# CY8C5888LTI_LP097 register map
File version: 0.1
CY8C58LP
Registers are 8-bit, read-write, no defined reset value unless marked. A register's access mark holds for its fields unless they carry their own. Offsets are from the block's base; lines under a group give offsets from that group; [hi:lo] are bit positions; {n}, {i} and the like mark numbered series; 'fields as' and 'values as' point back to an identical list; <NAME> marks a mode.

## Memory map
0x00000000 ADC_STATUS
0x00000000 BLINK_25HZ
0x00000000 ADC_SOC
0x00000000 ADC
0x00000000 BLINK_05HZ
0x00000000 LED_CTRL
0x00000000 BLINK_CTRL_EN
0x00000000 MOTOR_ON_OFF_1
0x00000000 VT1_DIR
0x00000000 VT2_DIR
0x00000000 MOTOR_DIR_1
0x00000000 PWM_MOTORS
0x00000000 PWM_VT
0x00000000 ADC_N_CHANNELS_USED
0x00000000 MY_TIMER_REG
0x00000000 MOTOR_ON_OFF_2
0x00000000 MOTOR_DRIVER_TYPE
0x00000000 CYCLES_TIMER
0x00000000 MOTOR_DIR_2
0x00000000 PACER_TIMER
0x00000000 RESET_FF
0x00000000 UART_RS485 — UART
0x00000000 FF_STATUS
0x00000000 MY_TIMER

## ADC_STATUS
Base 0x00000000
0x40006462 ADC_STATUS_STATUS_REG
0x40006482 ADC_STATUS_MASK_REG
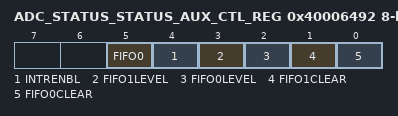
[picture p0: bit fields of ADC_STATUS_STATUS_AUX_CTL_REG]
0x40006492 ADC_STATUS_STATUS_AUX_CTL_REG
  [5] FIFO0 — FIFO0 clear
    1=ENABLED (Enable counter); 0=DISABLED (Disable counter)
  [4] INTRENBL — Enables or disables the Interrupt
    1=ENABLED (Interrupt enabled); 0=DISABLED (Interrupt disabled)
  [3] FIFO1LEVEL — FIFO level
    1=ENABLED (FIFO LVL: input mode: FIFO at least 1/2 empty; output mode: FIFO at least 1/2 full); 0=DISABLED (FIFO LVL: input mode: FIFO not full; output mode: FIFO not empty)
  [2] FIFO0LEVEL — FIFO level
    values as FIFO1LEVEL
  [1] FIFO1CLEAR — FIFO clear
    1=ENABLED (Clear FIFO state); 0=DISABLED (Normal FIFO operation)
  [0] FIFO0CLEAR — FIFO clear
    values as FIFO1CLEAR

## BLINK_25HZ
Base 0x00000000
0x40006425 BLINK_25HZ_COMPARE_Reg_ — UDB.D0 - Assigned Compare Value
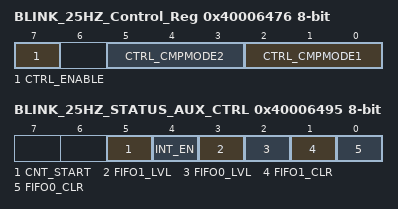
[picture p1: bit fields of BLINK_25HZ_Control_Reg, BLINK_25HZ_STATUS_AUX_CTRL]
0x40006476 BLINK_25HZ_Control_Reg — UDB Control Register - Assigned Control Register Value
  [7] CTRL_ENABLE — Enable the PWM
  [5:3] CTRL_CMPMODE2 — Compare mode 2
  [2:0] CTRL_CMPMODE1 — Compare mode 1
0x40006495 BLINK_25HZ_STATUS_AUX_CTRL — UDB Auxilliary Control Register
  [5] CNT_START — FIFO0 clear
    0=E_CNT_START0 (Disable counter); 1=E_CNT_START1 (Enable counter)
  [4] INT_EN
    0=E_INT_EN0 (Interrupt disabled); 1=E_INT_EN1 (Interrupt enabled)
  [3] FIFO1_LVL — FIFO level
    0=E_FIFO_LVL_0 (FIFO LVL: input mode: FIFO not full; output mode: FIFO not empty); 1=E_FIFO_LVL_1 (FIFO LVL: input mode: FIFO at least 1/2 empty; output mode: FIFO at least 1/2 full)
  [2] FIFO0_LVL — FIFO level
    values as FIFO1_LVL
  [1] FIFO1_CLR — FIFO1 clear
    0=E_FIFO_CLR_0 (Normal FIFO operation); 1=E_FIFO_CLR_1 (Clear FIFO state)
  [0] FIFO0_CLR — FIFO0 clear
    values as FIFO1_CLR

## ADC_SOC
Base 0x00000000
0x40006472 ADC_SOC_CONTROL_REG

## BLINK_05HZ
Base 0x00000000
0x40006526 BLINK_05HZ_COMPARE_Reg 16-bit — UDB.D0 - Assigned Compare Value
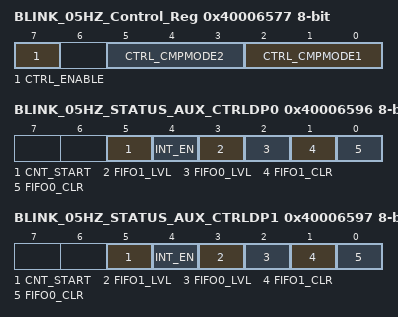
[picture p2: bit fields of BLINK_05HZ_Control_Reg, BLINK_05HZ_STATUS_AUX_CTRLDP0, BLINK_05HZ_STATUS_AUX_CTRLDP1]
0x40006577 BLINK_05HZ_Control_Reg — UDB Control Register - Assigned Control Register Value
  [7] CTRL_ENABLE — Enable the PWM
  [5:3] CTRL_CMPMODE2 — Compare mode 2
  [2:0] CTRL_CMPMODE1 — Compare mode 1
0x40006596 BLINK_05HZ_STATUS_AUX_CTRLDP0 — UDB Auxilliary Control Register
  [5] CNT_START — FIFO0 clear
    0=E_CNT_START0 (Disable counter); 1=E_CNT_START1 (Enable counter)
  [4] INT_EN
    0=E_INT_EN0 (Interrupt disabled); 1=E_INT_EN1 (Interrupt enabled)
  [3] FIFO1_LVL — FIFO level
    0=E_FIFO_LVL_0 (FIFO LVL: input mode: FIFO not full; output mode: FIFO not empty); 1=E_FIFO_LVL_1 (FIFO LVL: input mode: FIFO at least 1/2 empty; output mode: FIFO at least 1/2 full)
  [2] FIFO0_LVL — FIFO level
    values as FIFO1_LVL
  [1] FIFO1_CLR — FIFO1 clear
    0=E_FIFO_CLR_0 (Normal FIFO operation); 1=E_FIFO_CLR_1 (Clear FIFO state)
  [0] FIFO0_CLR — FIFO0 clear
    values as FIFO1_CLR
0x40006597 BLINK_05HZ_STATUS_AUX_CTRLDP1 — UDB Auxilliary Control Register
  fields as BLINK_05HZ_STATUS_AUX_CTRLDP0
